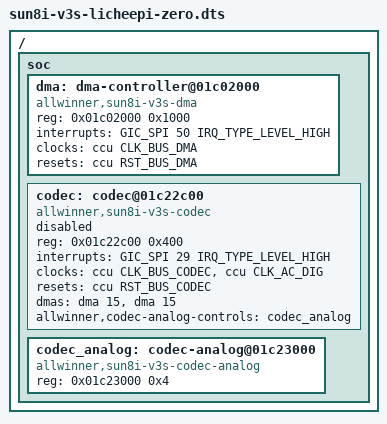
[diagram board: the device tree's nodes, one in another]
/* $NetBSD$ */

/*-
 * Copyright (c) 2021 Rui-Xiang Guo
 * All rights reserved.
 *
 * Redistribution and use in source and binary forms, with or without
 * modification, are permitted provided that the following conditions
 * are met:
 * 1. Redistributions of source code must retain the above copyright
 *    notice, this list of conditions and the following disclaimer.
 * 2. Redistributions in binary form must reproduce the above copyright
 *    notice, this list of conditions and the following disclaimer in the
 *    documentation and/or other materials provided with the distribution.
 *
 * THIS SOFTWARE IS PROVIDED BY THE AUTHOR ``AS IS'' AND ANY EXPRESS OR
 * IMPLIED WARRANTIES, INCLUDING, BUT NOT LIMITED TO, THE IMPLIED WARRANTIES
 * OF MERCHANTABILITY AND FITNESS FOR A PARTICULAR PURPOSE ARE DISCLAIMED.
 * IN NO EVENT SHALL THE AUTHOR BE LIABLE FOR ANY DIRECT, INDIRECT,
 * INCIDENTAL, SPECIAL, EXEMPLARY, OR CONSEQUENTIAL DAMAGES (INCLUDING,
 * BUT NOT LIMITED TO, PROCUREMENT OF SUBSTITUTE GOODS OR SERVICES;
 * LOSS OF USE, DATA, OR PROFITS; OR BUSINESS INTERRUPTION) HOWEVER CAUSED
 * AND ON ANY THEORY OF LIABILITY, WHETHER IN CONTRACT, STRICT LIABILITY,
 * OR TORT (INCLUDING NEGLIGENCE OR OTHERWISE) ARISING IN ANY WAY
 * OUT OF THE USE OF THIS SOFTWARE, EVEN IF ADVISED OF THE POSSIBILITY OF
 * SUCH DAMAGE.
 */

#include "../../../external/gpl2/dts/dist/arch/arm/boot/dts/sun8i-v3s-licheepi-zero.dts"

/ {
	soc {
		dma: dma-controller@01c02000 {
			compatible = "allwinner,sun8i-v3s-dma";
			reg = <0x01c02000 0x1000>;
			interrupts = <GIC_SPI 50 IRQ_TYPE_LEVEL_HIGH>;
			clocks = <&ccu CLK_BUS_DMA>;
			resets = <&ccu RST_BUS_DMA>;
			#dma-cells = <1>;
		};

		codec: codec@01c22c00 {
			#sound-dai-cells = <0>;
			compatible = "allwinner,sun8i-v3s-codec";
			reg = <0x01c22c00 0x400>;
			interrupts = <GIC_SPI 29 IRQ_TYPE_LEVEL_HIGH>;
			clocks = <&ccu CLK_BUS_CODEC>, <&ccu CLK_AC_DIG>;
			clock-names = "apb", "codec";
			resets = <&ccu RST_BUS_CODEC>;
			dmas = <&dma 15>, <&dma 15>;
			dma-names = "rx", "tx";
			allwinner,codec-analog-controls = <&codec_analog>;
			status = "disabled";
		};

		codec_analog: codec-analog@01c23000 {
			compatible = "allwinner,sun8i-v3s-codec-analog";
			reg = <0x01c23000 0x4>;
		};
	};
};
